AUTOSAR XML (schema 4-0-3)
package /PATAC/MSM/ComponentTypes
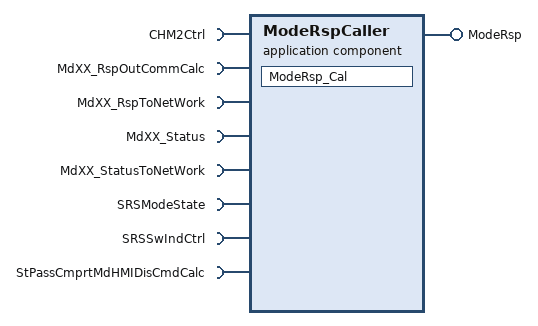
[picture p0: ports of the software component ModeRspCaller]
  application sw component type ModeRspCaller
    provide port ModeRsp: server-com-spec{operation=ModeRsp/Cal, queue-length=1}, provided-interface=ModeRsp
    8 x require port:
      CHM2Ctrl: client-com-spec=CHM2Ctrl/Cal, required-interface=CHM2Ctrl
      MdXX_RspOutCommCalc: client-com-spec=MdXX_RspOutCommCalc/Cal, required-interface=MdXX_RspOutCommCalc
      MdXX_RspToNetWork: client-com-spec=MdXX_RspToNetWork/Cal, required-interface=MdXX_RspToNetWork
      MdXX_Status: client-com-spec=MdXX_Status/Cal, required-interface=MdXX_Status
      MdXX_StatusToNetWork: client-com-spec=MdXX_StatusToNetWork/Cal, required-interface=MdXX_StatusToNetWork
      SRSModeState: client-com-spec=SRSModeState/Cal, required-interface=SRSModeState
      SRSSwIndCtrl: client-com-spec=SRSSwIndCtrl/Cal, required-interface=SRSSwIndCtrl
      StPassCmprtMdHMIDisCmdCalc: client-com-spec=StPassCmprtMdHMIDisCmdCalc/Cal, required-interface=StPassCmprtMdHMIDisCmdCalc
    behavior ModeRspCaller_InternalBehavior
      operation invoked event OIT_ModeRsp_Cal_ModeRsp_Cal: start-on-event=ModeRsp_Cal, operation=ModeRsp.Cal
      runnable ModeRsp_Cal
        8 x sync call, all with timeout=0:
          SC_CHM2Ctrl_Cal: operation=CHM2Ctrl.Cal
          SC_MdXX_RspOutCommCalc_Cal: operation=MdXX_RspOutCommCalc.Cal
          SC_MdXX_RspToNetWork_Cal: operation=MdXX_RspToNetWork.Cal
          SC_MdXX_Status_Cal: operation=MdXX_Status.Cal
          SC_MdXX_StatusToNetWork_Cal: operation=MdXX_StatusToNetWork.Cal
          SC_SRSModeState_Cal: operation=SRSModeState.Cal
          SC_SRSSwIndCtrl_Cal: operation=SRSSwIndCtrl.Cal
          SC_StPassCmprtMdHMIDisCmdCalc_Cal: operation=StPassCmprtMdHMIDisCmdCalc.Cal
  swc implementation ModeRspCaller_Implementation: behavior=ModeRspCaller_InternalBehavior
    code-descriptors:
      code Default: artifact-descriptors=autosar-engineering-object={short-label=Default, category=SWSRC}
package /PATAC/MSM/ModeAdjust/PortInterface
  9 x client server interface:
    CHM2Ctrl
      operation Cal
    MdXX_RspOutCommCalc
      operation Cal
    MdXX_RspToNetWork
      operation Cal
    MdXX_Status
      operation Cal
    MdXX_StatusToNetWork
      operation Cal
    ModeRsp
      operation Cal
    SRSModeState
      operation Cal
    SRSSwIndCtrl
      operation Cal
    StPassCmprtMdHMIDisCmdCalc
      operation Cal
